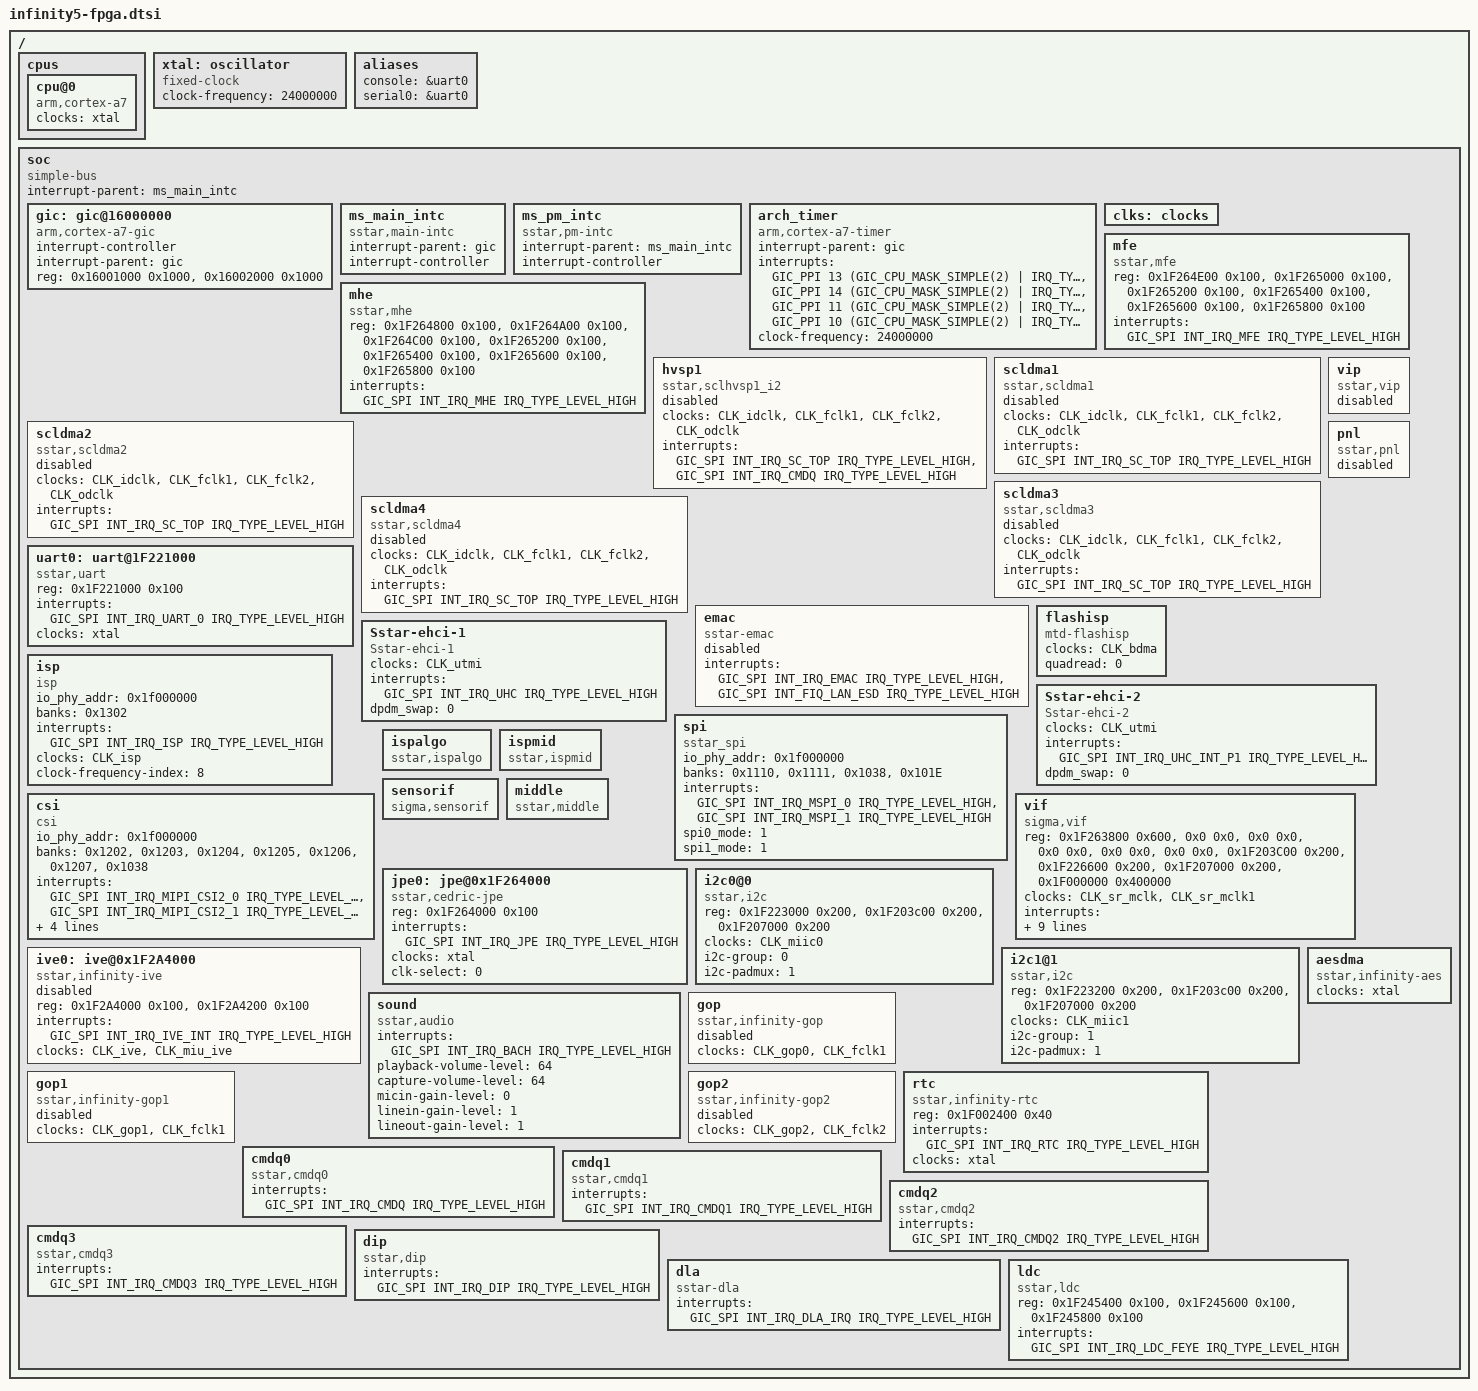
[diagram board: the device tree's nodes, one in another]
/*
* infinity5-fpga.dtsi- Sigmastar
*
* Copyright (c) [2019~2020] SigmaStar Technology.
*
*
* This software is licensed under the terms of the GNU General Public
* License version 2, as published by the Free Software Foundation, and
* may be copied, distributed, and modified under those terms.
*
* This program is distributed in the hope that it will be useful,
* but WITHOUT ANY WARRANTY; without even the implied warranty of
* MERCHANTABILITY or FITNESS FOR A PARTICULAR PURPOSE.  See the
* GNU General Public License version 2 for more details.
*
*/

#include <../../../../drivers/sstar/include/infinity5/irqs.h>
#include <../../../../drivers/sstar/include/infinity5/gpio.h>
#include <dt-bindings/interrupt-controller/irq.h>
#include <dt-bindings/interrupt-controller/arm-gic.h>
#include "skeleton.dtsi"


/ {
    cpus {
        #address-cells = <1>;
        #size-cells = <0>;

        cpu@0 {
            device_type = "cpu";
            compatible = "arm,cortex-a7";
            clocks = <&xtal>;
        };
    };

    xtal: oscillator {
        compatible = "fixed-clock";
        #clock-cells = <0>;
        clock-frequency = <24000000>;
    };

    aliases {
        console = &uart0;
        serial0 = &uart0;
    };

    soc {
        compatible = "simple-bus";
        interrupt-parent = <&ms_main_intc>;
        #address-cells = <1>;
        #size-cells = <1>;
        ranges;

        gic: gic@16000000 {
            compatible = "arm,cortex-a7-gic";
            #interrupt-cells = <3>;
            #address-cells = <1>;
            #size-cells = <1>;
            interrupt-controller;
            interrupt-parent = <&gic>;
            reg = <0x16001000 0x1000>,
                  <0x16002000 0x1000>;
        };

        ms_main_intc: ms_main_intc {
            compatible = "sstar,main-intc";
            #interrupt-cells = <3>;
            #address-cells = <1>;
            #size-cells = <1>;
            interrupt-parent=<&gic>;
            interrupt-controller;
        };

        ms_pm_intc: ms_pm_intc {
            compatible = "sstar,pm-intc";
            #interrupt-cells = <1>;
            interrupt-parent=<&ms_main_intc>;
            interrupt-controller;
        };

        arch_timer {
            compatible = "arm,cortex-a7-timer", "arm,armv7-timer";
            interrupt-parent=<&gic>;
            interrupts = <GIC_PPI 13 (GIC_CPU_MASK_SIMPLE(2) | IRQ_TYPE_LEVEL_LOW)>,
                         <GIC_PPI 14 (GIC_CPU_MASK_SIMPLE(2) | IRQ_TYPE_LEVEL_LOW)>,
                         <GIC_PPI 11 (GIC_CPU_MASK_SIMPLE(2) | IRQ_TYPE_LEVEL_LOW)>,
                         <GIC_PPI 10 (GIC_CPU_MASK_SIMPLE(2) | IRQ_TYPE_LEVEL_LOW)>;
            clock-frequency = <24000000>;  /* arch_timer must use clock-frequency*/
        };

        clks: clocks{
            #address-cells = <1>;
            #size-cells = <1>;
            ranges;
        };

/*
        timer_clockevent: timer@1F006040 {
            compatible = "sstar,piu-clockevent";
            reg = <0x1F006040 0x100>;
            interrupts=<GIC_SPI INT_FIQ_TIMER_0 IRQ_TYPE_LEVEL_HIGH>;
            clocks = <&CLK_xtali_12m>;
        };
*/
        mfe: mfe {
            compatible = "sstar,mfe";
            reg = <0x1F264E00 0x100>, <0x1F265000 0x100>, <0x1F265200 0x100>, <0x1F265400 0x100>, <0x1F265600 0x100>, <0x1F265800 0x100>;
            interrupts=<GIC_SPI INT_IRQ_MFE IRQ_TYPE_LEVEL_HIGH>;
            //clocks = <&xtal>;
            //clock-names = "CKG_mfe";
            status = "ok";
        };

        mhe: mhe {
            compatible = "sstar,mhe";
            reg = <0x1F264800 0x100>, <0x1F264A00 0x100>, <0x1F264C00 0x100>, <0x1F265200 0x100>, <0x1F265400 0x100>, <0x1F265600 0x100>, <0x1F265800 0x100>;
            interrupts=<GIC_SPI INT_IRQ_MHE IRQ_TYPE_LEVEL_HIGH>;
            //clocks = <&xtal>;
            //clock-names = "CKG_mhe";
            status = "ok";
        };

        hvsp1: hvsp1 {
            compatible = "sstar,sclhvsp1_i2";
            //reg = <0x1F000000 0x100>;
            //clk,chiptop,hvsp0,sc0,dnr,ldc
            clocks = <&CLK_idclk>,<&CLK_fclk1>,<&CLK_fclk2>,<&CLK_odclk>;
            clock-names = "CLK_idclk","CLK_fclk1","CLK_fclk2","CLK_odclk";
            status = "disabled";
            interrupts = <GIC_SPI INT_IRQ_SC_TOP IRQ_TYPE_LEVEL_HIGH>, <GIC_SPI INT_IRQ_CMDQ IRQ_TYPE_LEVEL_HIGH>;
        };

        scldma1: scldma1 {
            compatible = "sstar,scldma1";
            //reg = <0x1F000000 0x100>;
            //clk,chiptop,scldma
            clocks =  <&CLK_idclk>,<&CLK_fclk1>,<&CLK_fclk2>,<&CLK_odclk>;
            clock-names = "CLK_idclk","CLK_fclk1","CLK_fclk2","CLK_odclk";
            status = "disabled";
            interrupts = <GIC_SPI INT_IRQ_SC_TOP IRQ_TYPE_LEVEL_HIGH>;
        };
        scldma2: scldma2 {
            compatible = "sstar,scldma2";
            //reg = <0x1F000000 0x100>;
            //clk,chiptop,scldma
            clocks =  <&CLK_idclk>,<&CLK_fclk1>,<&CLK_fclk2>,<&CLK_odclk>;
            clock-names = "CLK_idclk","CLK_fclk1","CLK_fclk2","CLK_odclk";
            status = "disabled";
            interrupts = <GIC_SPI INT_IRQ_SC_TOP IRQ_TYPE_LEVEL_HIGH>;
        };
        scldma3: scldma3 {
            compatible = "sstar,scldma3";
            //reg = <0x1F000000 0x100>;
            //clk,chiptop,scldma
            clocks =  <&CLK_idclk>,<&CLK_fclk1>,<&CLK_fclk2>,<&CLK_odclk>;
            clock-names = "CLK_idclk","CLK_fclk1","CLK_fclk2","CLK_odclk";
            status = "disabled";
            interrupts = <GIC_SPI INT_IRQ_SC_TOP IRQ_TYPE_LEVEL_HIGH>;
        };
        scldma4: scldma4 {
            compatible = "sstar,scldma4";
            //reg = <0x1F000000 0x100>;
            //clk,chiptop,scldma
            clocks =  <&CLK_idclk>,<&CLK_fclk1>,<&CLK_fclk2>,<&CLK_odclk>;
            clock-names = "CLK_idclk","CLK_fclk1","CLK_fclk2","CLK_odclk";
            status = "disabled";
            interrupts = <GIC_SPI INT_IRQ_SC_TOP IRQ_TYPE_LEVEL_HIGH>;
        };

        vip: vip {
            compatible = "sstar,vip";
            status = "disabled";

            //reg = <0x1F224000 0x200>;
        };

        pnl: pnl {
            compatible = "sstar,pnl";
            status = "disabled";

            //Reg = <0x1F224000 0x200>;
        };

        uart0: uart@1F221000 {
            compatible = "sstar,uart";
            reg = <0x1F221000 0x100>;
            interrupts= <GIC_SPI INT_IRQ_UART_0 IRQ_TYPE_LEVEL_HIGH>;
            status = "ok";
            clocks = <&xtal>;
        };

        emac {
            compatible = "sstar-emac";
            interrupts = <GIC_SPI INT_IRQ_EMAC IRQ_TYPE_LEVEL_HIGH>, <GIC_SPI INT_FIQ_LAN_ESD IRQ_TYPE_LEVEL_HIGH>;
            status = "disable";
        };

        flashisp {
            compatible = "mtd-flashisp";
            clocks = <&CLK_bdma>;
            quadread = <0>;
            status = "ok";
        };

        Sstar-ehci-1 {
            compatible = "Sstar-ehci-1";
            clocks = <&CLK_utmi>;
            interrupts = <GIC_SPI INT_IRQ_UHC IRQ_TYPE_LEVEL_HIGH>;
            dpdm_swap=<0>;
            status = "ok";
        };

        Sstar-ehci-2 {
            compatible = "Sstar-ehci-2";
            clocks = <&CLK_utmi>;
            interrupts = <GIC_SPI INT_IRQ_UHC_INT_P1 IRQ_TYPE_LEVEL_HIGH>;
            dpdm_swap=<0>;
            status = "ok";
        };

        isp: isp {
            compatible = "isp";
            io_phy_addr = <0x1f000000>;
            banks = <0x1302>;
            interrupts = <GIC_SPI INT_IRQ_ISP IRQ_TYPE_LEVEL_HIGH>;
            clocks = <&CLK_isp>;
            status = "ok";
            clock-frequency-index = <8>;
        };

	spi: spi {
            compatible = "sstar_spi";
            io_phy_addr = <0x1f000000>;
            banks = <0x1110>,<0x1111>,<0x1038>,<0x101E>;
            interrupts = <GIC_SPI INT_IRQ_MSPI_0 IRQ_TYPE_LEVEL_HIGH>,<GIC_SPI INT_IRQ_MSPI_1 IRQ_TYPE_LEVEL_HIGH>;
            spi0_mode = <1>;
            spi1_mode = <1>;
            status = "ok";
        };

        csi: csi {
            compatible = "csi";
            io_phy_addr = <0x1f000000>;
            banks = <0x1202>,<0x1203>,<0x1204>,<0x1205>,<0x1206>,<0x1207>,<0x1038>;
            interrupts = <GIC_SPI INT_IRQ_MIPI_CSI2_0 IRQ_TYPE_LEVEL_HIGH>,<GIC_SPI INT_IRQ_MIPI_CSI2_1 IRQ_TYPE_LEVEL_HIGH>;
            clocks = <&CLK_csi_mac_lptx_top_i_0>,<&CLK_csi_mac_top_i_0>,<&CLK_csi_ns_top_i_0>,<&CLK_csi_mac_lptx_top_i_1>,<&CLK_csi_mac_top_i_1>,<&CLK_csi_ns_top_i_1>;
            status = "ok";
        };

        vif: vif {
            compatible = "sigma,vif";
            status = "ok";
            reg = <0x1F263800 0x600>, <0x0 0x0>, <0x0 0x0>, <0x0 0x0>, <0x0 0x0>, <0x0 0x0>, <0x1F203C00 0x200>, <0x1F226600 0x200>, <0x1F207000 0x200>, <0x1F000000 0x400000>;
            clocks = <&CLK_sr_mclk>,<&CLK_sr_mclk1>;
            interrupts = <GIC_SPI INT_IRQ_VIF IRQ_TYPE_LEVEL_HIGH>;
            /* Config sensor 0 pad mux */
            vif_sr0_par_mode = <6>;
            vif_sr0_mipi_mode_2lane = <2>;
            vif_sr0_mipi_mode_4lane = <1>;
            vif_sr0_bt656_mode = <1>;
            /* Config sensor 1 pad mux */
            vif_sr1_par_mode = <1>;
            vif_sr1_mipi_mode_1lane = <2>;
            vif_sr1_mipi_mode_2lane = <1>;
            vif_sr1_bt656_mode = <1>;
        };

        ispalgo: ispalgo {
            compatible = "sstar,ispalgo";
            status = "ok";
        };

        ispmid: ispmid {
            compatible = "sstar,ispmid";
            status = "ok";
        };

        sensorif: sensorif {
            compatible = "sigma,sensorif";
            status = "ok";
        };

        middle: middle {
            compatible = "sstar,middle";
            status = "ok";
        };

        jpe0: jpe@0x1F264000 {
            compatible = "sstar,cedric-jpe";
            reg = <0x1F264000 0x100>;
            interrupts = <GIC_SPI INT_IRQ_JPE IRQ_TYPE_LEVEL_HIGH>;
            clocks = <&xtal>;
            clock-names = "CKG_jpe";
            clk-select = <0>; // 0: 288MHz  1: 216MHz  2: 54MHz  3: 27MHz
            status = "ok";
        };

        ive0: ive@0x1F2A4000 {
            compatible = "sstar,infinity-ive";
            reg = <0x1F2A4000 0x100>,<0x1F2A4200 0x100>;
            interrupts = <GIC_SPI INT_IRQ_IVE_INT IRQ_TYPE_LEVEL_HIGH>;
            clocks = <&CLK_ive>,<&CLK_miu_ive>;
            status = "disabled";
        };

        i2c0@0{
            compatible = "sstar,i2c";
            reg = <0x1F223000 0x200>,<0x1F203c00 0x200>,<0x1F207000 0x200>;
                #address-cells = <1>;
                #size-cells = <0>;
            clocks = <&CLK_miic0>;
            i2c-group = <0>;
            status = "ok";
            /*
             * padmux: 1 -> PAD_I2C0_SCL, PAD_I2C0_SDA
             *         2 -> PAD_PWM0, PAD_PWM1
             *         3 -> PAD_SNR0_D0, PAD_SNR0_D1
            */
            i2c-padmux = <1>;
        };

        i2c1@1{
            compatible = "sstar,i2c";
            reg = <0x1F223200 0x200>,<0x1F203c00 0x200>,<0x1F207000 0x200>;
                #address-cells = <1>;
                #size-cells = <0>;
            clocks = <&CLK_miic1>;
            i2c-group = <1>;
            /*
             * padmux: 1 -> PAD_I2C1_SCL, PAD_I2C1_SDA
             *         2 -> PAD_PWM0, PAD_PWM1
             *         3 -> PAD_SNR0_GPIO2, PAD_SNR0_GPIO4
             *         4 -> PAD_SNR1_GPIO5, PAD_SNR1_GPIO6
            */
            i2c-padmux = <1>;
            status = "ok";
        };
        sound {
            compatible = "sstar,audio";
//            reg = <0x1F000000 0x1000000>;
            interrupts=<GIC_SPI INT_IRQ_BACH IRQ_TYPE_LEVEL_HIGH>;
            playback-volume-level=<64>;    //0~76
            capture-volume-level=<64>;
            micin-gain-level=<0>;    //0~5
            linein-gain-level=<1>;//0~6
            lineout-gain-level=<1>;//0~2
        };

        aesdma {
            compatible = "sstar,infinity-aes";
            clocks = <&xtal>;
            status = "ok";
        };

        gop{
            compatible = "sstar,infinity-gop";
            clocks = <&CLK_gop0>,<&CLK_fclk1>;
            status = "disabled";
        };

        gop1{
            compatible = "sstar,infinity-gop1";
            clocks = <&CLK_gop1>,<&CLK_fclk1>;
            status = "disabled";
        };

        gop2{
            compatible = "sstar,infinity-gop2";
            clocks = <&CLK_gop2>,<&CLK_fclk2>;
            status = "disabled";
        };

        rtc {
            compatible = "sstar,infinity-rtc";
            reg = <0x1F002400 0x40>;
            interrupts=<GIC_SPI INT_IRQ_RTC IRQ_TYPE_LEVEL_HIGH>;
            clocks =  <&xtal>;
            status = "ok";
        };

        cmdq0 {
            compatible = "sstar,cmdq0";
            interrupts=<GIC_SPI INT_IRQ_CMDQ IRQ_TYPE_LEVEL_HIGH>;
            status = "ok";
        };

        cmdq1 {
            compatible = "sstar,cmdq1";
            interrupts=<GIC_SPI INT_IRQ_CMDQ1 IRQ_TYPE_LEVEL_HIGH>;
            status = "ok";
        };

        cmdq2 {
            compatible = "sstar,cmdq2";
            interrupts=<GIC_SPI INT_IRQ_CMDQ2 IRQ_TYPE_LEVEL_HIGH>;
            status = "ok";
        };

        cmdq3 {
            compatible = "sstar,cmdq3";
            interrupts=<GIC_SPI INT_IRQ_CMDQ3 IRQ_TYPE_LEVEL_HIGH>;
            status = "ok";
        };

        dip {
            compatible = "sstar,dip";
            interrupts=<GIC_SPI INT_IRQ_DIP IRQ_TYPE_LEVEL_HIGH>;
            status = "ok";
        };

        dla: dla {
            compatible = "sstar-dla";
            interrupts=<GIC_SPI INT_IRQ_DLA_IRQ IRQ_TYPE_LEVEL_HIGH>;
            status = "ok";
        };

        ldc: ldc {
            compatible = "sstar,ldc";
            reg = <0x1F245400 0x100>, <0x1F245600 0x100>, <0x1F245800 0x100>;
            interrupts=<GIC_SPI INT_IRQ_LDC_FEYE IRQ_TYPE_LEVEL_HIGH>;
            //clocks = <&xtal>;
            //clock-names = "CKG_ldc";
            //clk-select = <0>; // 0: 288MHz  1: 86MHz  2: 216MHz  3: 320MHz
            status = "ok";
        };
    };
};

&clks {
    #include <../../../../drivers/sstar/include/infinity5/reg_clks.h>
    #include "infinity5-clks.dtsi"
};

